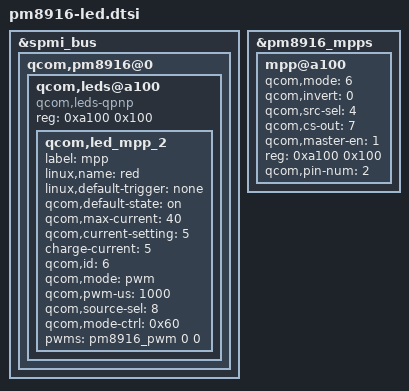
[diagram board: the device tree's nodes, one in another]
/* Copyright (c) 2014, The Linux Foundation. All rights reserved.
 *
 * This program is free software; you can redistribute it and/or modify
 * it under the terms of the GNU General Public License version 2 and
 * only version 2 as published by the Free Software Foundation.
 *
 * This program is distributed in the hope that it will be useful,
 * but WITHOUT ANY WARRANTY; without even the implied warranty of
 * MERCHANTABILITY or FITNESS FOR A PARTICULAR PURPOSE.  See the
 * GNU General Public License for more details.
 */

&spmi_bus {
	qcom,pm8916@0 {
		qcom,leds@a100 {
			compatible = "qcom,leds-qpnp";
			reg = <0xa100 0x100>;
			status = "okay";
			qcom,led_mpp_2 {
				label = "mpp";
				linux,name = "red";
				linux,default-trigger = "none";
				qcom,default-state = "on";
				qcom,max-current = <40>;
				qcom,current-setting = <5>;
                                charge-current = <5>;
				qcom,id = <6>;
				qcom,mode = "pwm";
                                qcom,pwm-us = <1000>;
				qcom,source-sel = <8>;
				qcom,mode-ctrl = <0x60>;
                                pwms = <&pm8916_pwm 0 0>;
			};
		};
	};
};

&pm8916_mpps {
	mpp@a100 {
		status = "okay";
		qcom,mode = <6>;
		qcom,invert = <0>;
		qcom,src-sel = <4>;
		qcom,cs-out = <7>;
		qcom,master-en = <1>;
		reg = <0xa100 0x100>;
		qcom,pin-num = <2>;
	};
};
